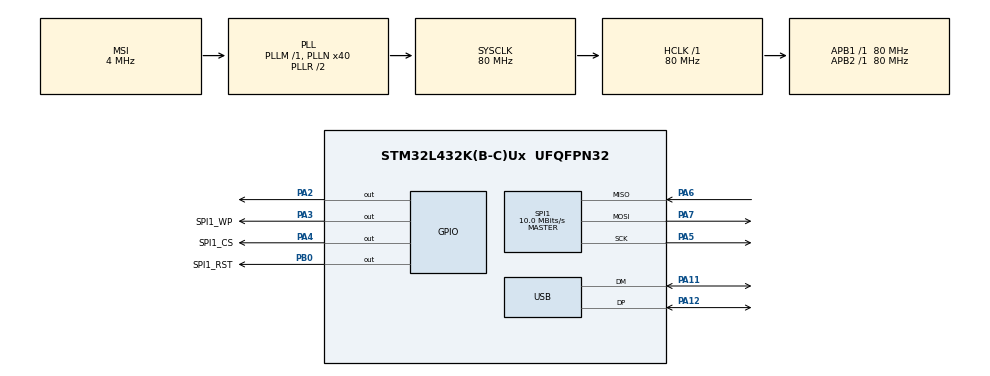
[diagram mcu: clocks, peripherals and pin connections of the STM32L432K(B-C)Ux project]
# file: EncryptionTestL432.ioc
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Mcu.Family=STM32L4
Mcu.Name=STM32L432K(B-C)Ux
Mcu.Package=UFQFPN32
NVIC.PriorityGroup=NVIC_PRIORITYGROUP_4
NVIC.USB_IRQn=true\:0\:0\:false\:false\:true\:false\:true
PA11.Mode=Device
PA11.Signal=USB_DM
PA12.Mode=Device
PA12.Signal=USB_DP
PA13\ (JTMS-SWDIO).Mode=Trace_Asynchronous_SW
PA13\ (JTMS-SWDIO).Signal=SYS_JTMS-SWDIO
PA14\ (JTCK-SWCLK).Mode=Trace_Asynchronous_SW
PA14\ (JTCK-SWCLK).Signal=SYS_JTCK-SWCLK
PA2.Signal=GPIO_Output
PA3.GPIO_Label=SPI1_WP
PA3.Signal=GPIO_Output
PA4.GPIO_Label=SPI1_CS
PA4.Signal=GPIO_Output
PA5.Mode=Full_Duplex_Master
PA5.Signal=SPI1_SCK
PA6.Mode=Full_Duplex_Master
PA6.Signal=SPI1_MISO
PA7.Mode=Full_Duplex_Master
PA7.Signal=SPI1_MOSI
PB0.GPIO_Label=SPI1_RST
PB0.Signal=GPIO_Output
PB3\ (JTDO-TRACESWO).Mode=Trace_Asynchronous_SW
PB3\ (JTDO-TRACESWO).Signal=SYS_JTDO-SWO
ProjectManager.HeapSize=0x200
ProjectManager.StackSize=0x400
ProjectManager.TargetToolchain=STM32CubeIDE
RCC.ADCFreq_Value=48000000
RCC.AHBFreq_Value=80000000
RCC.APB1Freq_Value=80000000
RCC.APB1TimFreq_Value=80000000
RCC.APB2Freq_Value=80000000
RCC.APB2TimFreq_Value=80000000
RCC.CortexFreq_Value=80000000
RCC.HCLKFreq_Value=80000000
RCC.HSE_VALUE=8000000
RCC.HSI48_VALUE=48000000
RCC.HSI_VALUE=16000000
RCC.LSE_VALUE=32768
RCC.MSI_VALUE=4000000
RCC.PLLN=40
RCC.PLLSAI1N=24
RCC.SYSCLKFreq_VALUE=80000000
RCC.SYSCLKSource=RCC_SYSCLKSOURCE_PLLCLK
RCC.USBFreq_Value=48000000
RCC.VCOOutputFreq_Value=160000000
SPI1.BaudRatePrescaler=SPI_BAUDRATEPRESCALER_8
SPI1.CalculateBaudRate=10.0 MBits/s
SPI1.DataSize=SPI_DATASIZE_8BIT
SPI1.Direction=SPI_DIRECTION_2LINES
SPI1.Mode=SPI_MODE_MASTER
SPI1.VirtualType=VM_MASTER
USB.Sof_enable=DISABLE
USB_DEVICE.CLASS_NAME_FS=CDC
USB_DEVICE.MANUFACTURER_STRING=ITnnovative
USB_DEVICE.PRODUCT_STRING_CDC_FS=Encryption Module
USB_DEVICE.VirtualMode=Cdc
USB_DEVICE.VirtualModeFS=Cdc_FS
VP_USB_DEVICE_VS_USB_DEVICE_CDC_FS.Mode=CDC_FS
board=custom

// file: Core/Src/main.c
/* USER CODE BEGIN Header */
/**
  ******************************************************************************
  * @file           : main.c
  * @brief          : Main program body
  ******************************************************************************
  * @attention
  *
  * <h2><center>&copy; Copyright (c) 2021 STMicroelectronics.
  * All rights reserved.</center></h2>
  *
  * This software component is licensed by ST under Ultimate Liberty license
  * SLA0044, the "License"; You may not use this file except in compliance with
  * the License. You may obtain a copy of the License at:
  *                             www.st.com/SLA0044
  *
  ******************************************************************************
  */
/* USER CODE END Header */
#include <processing.h>
#include "main.h"
#include "usb_device.h"
#include "peripheral/usb.h"

#include "processing.h"

/* USER CODE BEGIN Includes */
#include "peripheral/w25qxx.h"
/* USER CODE END Includes */

SPI_HandleTypeDef hspi1;

void SystemClock_Config(void);
static void MX_GPIO_Init(void);
static void MX_SPI1_Init(void);

int main(void)
{

  /* MCU Configuration--------------------------------------------------------*/

  /* Reset of all peripherals, Initializes the Flash interface and the Systick. */
  HAL_Init();

  /* Configure the system clock */
  SystemClock_Config();

  /* Initialize all configured peripherals */
  MX_GPIO_Init();
  MX_USB_DEVICE_Init();
  MX_SPI1_Init();
  /* USER CODE BEGIN 2 */
  HAL_GPIO_WritePin(SPI1_WP_GPIO_Port, SPI1_WP_Pin, GPIO_PIN_SET);
  HAL_GPIO_WritePin(SPI1_RST_GPIO_Port, SPI1_RST_Pin, GPIO_PIN_SET);
  W25qxx_Init();

  /* USER CODE END 2 */

  /* Infinite loop */
  /* USER CODE BEGIN WHILE */
  while (1)
  {
	  if(has_data()){

		  ProcessByte(get_data());

		  increase_counter();
	  }

    /* USER CODE END WHILE */

  }
}

void SystemClock_Config(void)
{
  RCC_OscInitTypeDef RCC_OscInitStruct = {0};
  RCC_ClkInitTypeDef RCC_ClkInitStruct = {0};
  RCC_PeriphCLKInitTypeDef PeriphClkInit = {0};

  /** Initializes the RCC Oscillators according to the specified parameters
  * in the RCC_OscInitTypeDef structure.
  */
  RCC_OscInitStruct.OscillatorType = RCC_OSCILLATORTYPE_MSI;
  RCC_OscInitStruct.MSIState = RCC_MSI_ON;
  RCC_OscInitStruct.MSICalibrationValue = 0;
  RCC_OscInitStruct.MSIClockRange = RCC_MSIRANGE_6;
  RCC_OscInitStruct.PLL.PLLState = RCC_PLL_ON;
  RCC_OscInitStruct.PLL.PLLSource = RCC_PLLSOURCE_MSI;
  RCC_OscInitStruct.PLL.PLLM = 1;
  RCC_OscInitStruct.PLL.PLLN = 40;
  RCC_OscInitStruct.PLL.PLLP = RCC_PLLP_DIV7;
  RCC_OscInitStruct.PLL.PLLQ = RCC_PLLQ_DIV2;
  RCC_OscInitStruct.PLL.PLLR = RCC_PLLR_DIV2;
  if (HAL_RCC_OscConfig(&RCC_OscInitStruct) != HAL_OK)
  {
    Error_Handler();
  }
  /** Initializes the CPU, AHB and APB buses clocks
  */
  RCC_ClkInitStruct.ClockType = RCC_CLOCKTYPE_HCLK|RCC_CLOCKTYPE_SYSCLK
                              |RCC_CLOCKTYPE_PCLK1|RCC_CLOCKTYPE_PCLK2;
  RCC_ClkInitStruct.SYSCLKSource = RCC_SYSCLKSOURCE_PLLCLK;
  RCC_ClkInitStruct.AHBCLKDivider = RCC_SYSCLK_DIV1;
  RCC_ClkInitStruct.APB1CLKDivider = RCC_HCLK_DIV1;
  RCC_ClkInitStruct.APB2CLKDivider = RCC_HCLK_DIV1;

  if (HAL_RCC_ClockConfig(&RCC_ClkInitStruct, FLASH_LATENCY_4) != HAL_OK)
  {
    Error_Handler();
  }
  PeriphClkInit.PeriphClockSelection = RCC_PERIPHCLK_USB;
  PeriphClkInit.UsbClockSelection = RCC_USBCLKSOURCE_PLLSAI1;
  PeriphClkInit.PLLSAI1.PLLSAI1Source = RCC_PLLSOURCE_MSI;
  PeriphClkInit.PLLSAI1.PLLSAI1M = 1;
  PeriphClkInit.PLLSAI1.PLLSAI1N = 24;
  PeriphClkInit.PLLSAI1.PLLSAI1P = RCC_PLLP_DIV7;
  PeriphClkInit.PLLSAI1.PLLSAI1Q = RCC_PLLQ_DIV2;
  PeriphClkInit.PLLSAI1.PLLSAI1R = RCC_PLLR_DIV2;
  PeriphClkInit.PLLSAI1.PLLSAI1ClockOut = RCC_PLLSAI1_48M2CLK;
  if (HAL_RCCEx_PeriphCLKConfig(&PeriphClkInit) != HAL_OK)
  {
    Error_Handler();
  }
  /** Configure the main internal regulator output voltage
  */
  if (HAL_PWREx_ControlVoltageScaling(PWR_REGULATOR_VOLTAGE_SCALE1) != HAL_OK)
  {
    Error_Handler();
  }
}

static void MX_SPI1_Init(void)
{

  /* SPI1 parameter configuration*/
  hspi1.Instance = SPI1;
  hspi1.Init.Mode = SPI_MODE_MASTER;
  hspi1.Init.Direction = SPI_DIRECTION_2LINES;
  hspi1.Init.DataSize = SPI_DATASIZE_8BIT;
  hspi1.Init.CLKPolarity = SPI_POLARITY_LOW;
  hspi1.Init.CLKPhase = SPI_PHASE_1EDGE;
  hspi1.Init.NSS = SPI_NSS_SOFT;
  hspi1.Init.BaudRatePrescaler = SPI_BAUDRATEPRESCALER_8;
  hspi1.Init.FirstBit = SPI_FIRSTBIT_MSB;
  hspi1.Init.TIMode = SPI_TIMODE_DISABLE;
  hspi1.Init.CRCCalculation = SPI_CRCCALCULATION_DISABLE;
  hspi1.Init.CRCPolynomial = 7;
  hspi1.Init.CRCLength = SPI_CRC_LENGTH_DATASIZE;
  hspi1.Init.NSSPMode = SPI_NSS_PULSE_ENABLE;
  if (HAL_SPI_Init(&hspi1) != HAL_OK)
  {
    Error_Handler();
  }

}

static void MX_GPIO_Init(void)
{
  GPIO_InitTypeDef GPIO_InitStruct = {0};

  /* GPIO Ports Clock Enable */
  __HAL_RCC_GPIOA_CLK_ENABLE();
  __HAL_RCC_GPIOB_CLK_ENABLE();

  /*Configure GPIO pin Output Level */
  HAL_GPIO_WritePin(GPIOA, GPIO_PIN_2|SPI1_WP_Pin|SPI1_CS_Pin, GPIO_PIN_RESET);

  /*Configure GPIO pin Output Level */
  HAL_GPIO_WritePin(SPI1_RST_GPIO_Port, SPI1_RST_Pin, GPIO_PIN_RESET);

  /*Configure GPIO pins : PA2 SPI1_WP_Pin SPI1_CS_Pin */
  GPIO_InitStruct.Pin = GPIO_PIN_2|SPI1_WP_Pin|SPI1_CS_Pin;
  GPIO_InitStruct.Mode = GPIO_MODE_OUTPUT_PP;
  GPIO_InitStruct.Pull = GPIO_NOPULL;
  GPIO_InitStruct.Speed = GPIO_SPEED_FREQ_LOW;
  HAL_GPIO_Init(GPIOA, &GPIO_InitStruct);

  /*Configure GPIO pin : SPI1_RST_Pin */
  GPIO_InitStruct.Pin = SPI1_RST_Pin;
  GPIO_InitStruct.Mode = GPIO_MODE_OUTPUT_PP;
  GPIO_InitStruct.Pull = GPIO_NOPULL;
  GPIO_InitStruct.Speed = GPIO_SPEED_FREQ_LOW;
  HAL_GPIO_Init(SPI1_RST_GPIO_Port, &GPIO_InitStruct);

}

void Error_Handler(void)
{
}

/************************ (C) COPYRIGHT STMicroelectronics *****END OF FILE****/
